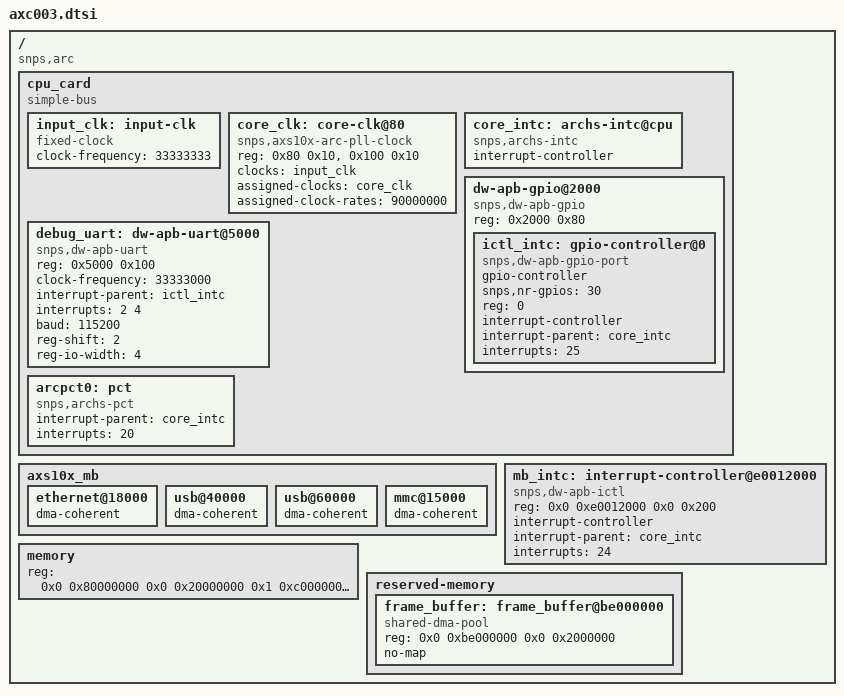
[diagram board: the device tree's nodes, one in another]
/include/ "skeleton_hs.dtsi"
/ {
	compatible = "snps,arc";
	#address-cells = <2>;
	#size-cells = <2>;
	cpu_card {
		compatible = "simple-bus";
		#address-cells = <1>;
		#size-cells = <1>;
		ranges = <0x00000000 0x0 0xf0000000 0x10000000>;
		input_clk: input-clk {
			#clock-cells = <0>;
			compatible = "fixed-clock";
			clock-frequency = <33333333>;
		};
		core_clk: core-clk@80 {
			compatible = "snps,axs10x-arc-pll-clock";
			reg = <0x80 0x10>, <0x100 0x10>;
			#clock-cells = <0>;
			clocks = <&input_clk>;
			assigned-clocks = <&core_clk>;
			assigned-clock-rates = <90000000>;
		};
		core_intc: archs-intc@cpu {
			compatible = "snps,archs-intc";
			interrupt-controller;
			#interrupt-cells = <1>;
		};
		dw-apb-gpio@2000 {
			compatible = "snps,dw-apb-gpio";
			reg = < 0x2000 0x80 >;
			#address-cells = <1>;
			#size-cells = <0>;
			ictl_intc: gpio-controller@0 {
				compatible = "snps,dw-apb-gpio-port";
				gpio-controller;
				#gpio-cells = <2>;
				snps,nr-gpios = <30>;
				reg = <0>;
				interrupt-controller;
				#interrupt-cells = <2>;
				interrupt-parent = <&core_intc>;
				interrupts = <25>;
			};
		};
		debug_uart: dw-apb-uart@5000 {
			compatible = "snps,dw-apb-uart";
			reg = <0x5000 0x100>;
			clock-frequency = <33333000>;
			interrupt-parent = <&ictl_intc>;
			interrupts = <2 4>;
			baud = <115200>;
			reg-shift = <2>;
			reg-io-width = <4>;
		};
		arcpct0: pct {
			compatible = "snps,archs-pct";
			#interrupt-cells = <1>;
			interrupt-parent = <&core_intc>;
			interrupts = <20>;
		};
	};
	axs10x_mb {
		ethernet@18000 {
			dma-coherent;
		};
		usb@40000 {
			dma-coherent;
		};
		usb@60000 {
			dma-coherent;
		};
		mmc@15000 {
			dma-coherent;
		};
	};
	mb_intc: interrupt-controller@e0012000 {
		#interrupt-cells = <1>;
		compatible = "snps,dw-apb-ictl";
		reg = < 0x0 0xe0012000 0x0 0x200 >;
		interrupt-controller;
		interrupt-parent = <&core_intc>;
		interrupts = < 24 >;
	};
	memory {
		device_type = "memory";
		reg = <0x0 0x80000000 0x0 0x20000000	 
		       0x1 0xc0000000 0x0 0x40000000>;	 
	};
	reserved-memory {
		#address-cells = <2>;
		#size-cells = <2>;
		ranges;
		frame_buffer: frame_buffer@be000000 {
			compatible = "shared-dma-pool";
			reg = <0x0 0xbe000000 0x0 0x2000000>;
			no-map;
		};
	};
};
